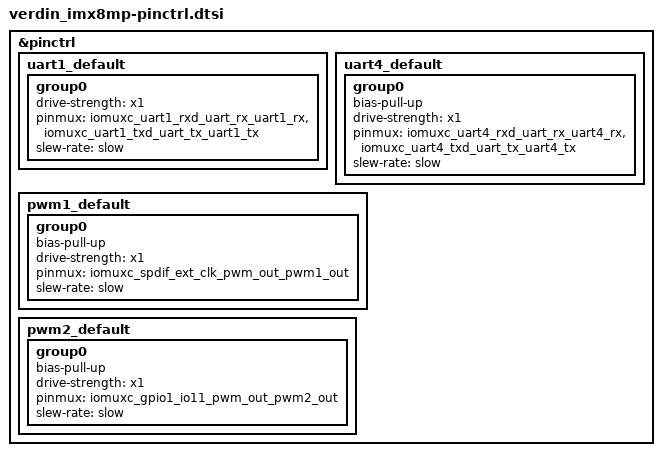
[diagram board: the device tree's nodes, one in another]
/*
 * Copyright (c) 2023 Toradex
 *
 * SPDX-License-Identifier: Apache-2.0
 */

#include <nxp/imx/pinctrl/mimx8ml8dvnlz-pinctrl.dtsi>

&pinctrl {
	uart1_default: uart1_default {
		group0 {
			drive-strength = "x1";
			pinmux = <&iomuxc_uart1_rxd_uart_rx_uart1_rx>,
				 <&iomuxc_uart1_txd_uart_tx_uart1_tx>;
			slew-rate = "slow";
		};
	};

	uart4_default: uart4_default {
		group0 {
			bias-pull-up;
			drive-strength = "x1";
			pinmux = <&iomuxc_uart4_rxd_uart_rx_uart4_rx>,
				 <&iomuxc_uart4_txd_uart_tx_uart4_tx>;
			slew-rate = "slow";
		};
	};

	pwm1_default: pwm1_default {
		group0 {
			bias-pull-up;
			drive-strength = "x1";
			pinmux = <&iomuxc_spdif_ext_clk_pwm_out_pwm1_out>;
			slew-rate = "slow";
		};
	};

	pwm2_default: pwm2_default {
		group0 {
			bias-pull-up;
			drive-strength = "x1";
			pinmux = <&iomuxc_gpio1_io11_pwm_out_pwm2_out>;
			slew-rate = "slow";
		};
	};
};
